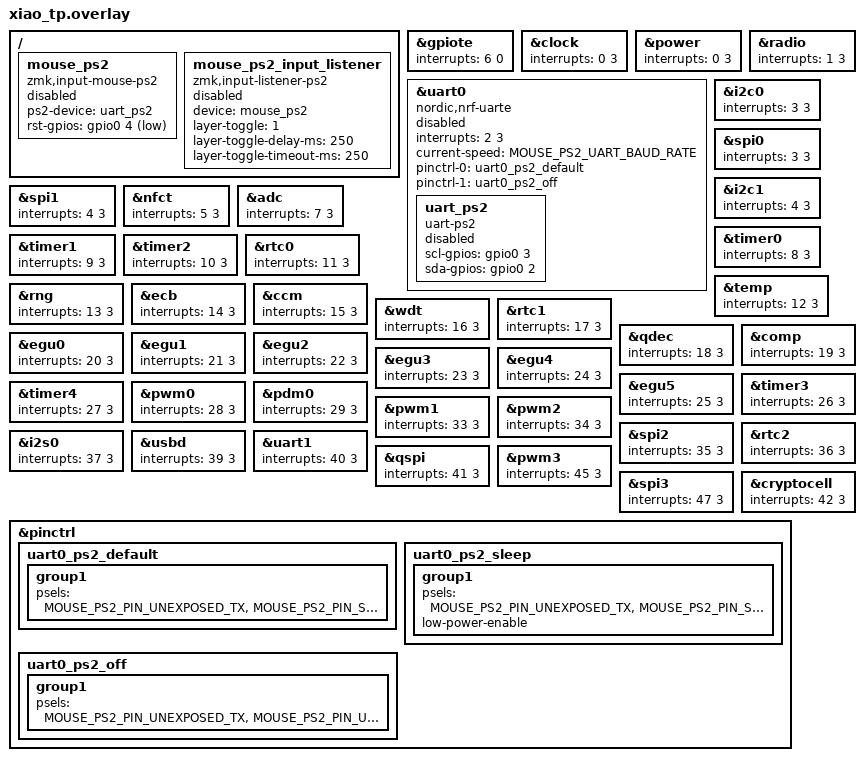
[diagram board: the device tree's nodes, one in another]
/*
 * XIAO TrackPoint Only Shield - PS/2 Configuration
 * Based on corne_tp_right.overlay but adapted for Seeed XIAO BLE
 */

#include "xiao_tp.dtsi"

// Pick the PS/2 driver - Use UART driver for better performance
#define MOUSE_PS2_DRIVER_UART

// Configure pins for Seeed XIAO BLE
// XIAO BLE pin mapping:
// D0 = P0.02, D1 = P0.03, D2 = P0.04, D3 = P0.05, D4 = P0.06, D5 = P0.07
// D6 = P0.08, D7 = P0.09, D8 = P0.10, D9 = P0.11, D10 = P0.12, D11 = P0.13
// PS/2 protocol requires pull-up resistors (4.7kΩ recommended)
// Note: UART handles reading, GPIO handles writing

// Configure SDA pin using pinctrl notation for XIAO BLE
#define MOUSE_PS2_PIN_SDA_PINCTRL <NRF_PSEL(UART_RX, 0, 2)>

// Configure UART BAUD Rate (use default 14400 like Corne example)
#define MOUSE_PS2_UART_BAUD_RATE <14400>

// Unexposed UART pins for XIAO BLE
#define MOUSE_PS2_PIN_UNEXPOSED_TX <NRF_PSEL(UART_TX, 0, 27)>
#define MOUSE_PS2_PIN_UNEXPOSED_RX <NRF_PSEL(UART_RX, 0, 28)>

// Optional: Configure RESET pin if needed (D2 = P0.04)
#define MOUSE_PS2_PIN_RST_PRO_MICRO

// This define can be used in the keymap file to check whether the device tree
// configs in this file are present
#define MOUSE_PS2_DT_PRESENT

// Adjust GPIO interrupt priority to the highest level.
//
// IMPORTANT TLDR:
// PS/2 events must be processed within 30-50us, but frequently bluetooth and
// other interrupts take longer to finish.
//
// Therefore we change the default GPIO priority to the highest level (0) and
// demote all BT interrupt priorities by one level using the kconfig settings:
// - CONFIG_BT_CTLR_LLL_PRIO 1
// - CONFIG_BT_CTLR_ULL_HIGH_PRIO 2
// - CONFIG_BT_CTLR_ULL_LOW_PRIOCONFIG 2
//
// These config options are enabled automatically by the PS2 UART and GPIO
// drivers... so you don't have to enable them manually.
//
// Then we lower the interrupt priority of all other devices by 2 levels using
// the devicetree config below.
//
// This allows the PS/2 interrupts to be triggered faster and reduces
// transmission errors.

// gpiote should have the highest interrupt priority (0)
&gpiote {
    interrupts = < 6 0 >;
};

// All other priorities should be two levels lower than their defaults
// (which is usually 1 and should be demoted to 3)
&clock {
    interrupts = < 0 3 >;
};

&power {
    interrupts = < 0 3 >;
};

&radio {
    interrupts = < 1 3 >;
};

&uart0 {
    interrupts = < 2 3 >;
};

&i2c0 {
    interrupts = < 3 3 >;
};

&spi0 {
    interrupts = < 3 3 >;
};

&i2c1 {
    interrupts = < 4 3 >;
};

&spi1 {
    interrupts = < 4 3 >;
};

&nfct {
    interrupts = < 5 3 >;
};

&adc {
    interrupts = < 7 3 >;
};

&timer0 {
    interrupts = < 8 3 >;
};

&timer1 {
    interrupts = < 9 3 >;
};

&timer2 {
    interrupts = < 10 3 >;
};

&rtc0 {
    interrupts = < 11 3 >;
};

&temp {
    interrupts = < 12 3 >;
};

&rng {
    interrupts = < 13 3 >;
};

&ecb {
    interrupts = < 14 3 >;
};

&ccm {
    interrupts = < 15 3 >;
};

&wdt {
    interrupts = < 16 3 >;
};

&rtc1 {
    interrupts = < 17 3 >;
};

&qdec {
    interrupts = < 18 3 >;
};

&comp {
    interrupts = < 19 3 >;
};

&egu0 {
    interrupts = < 20 3 >;
};

&egu1 {
    interrupts = < 21 3 >;
};

&egu2 {
    interrupts = < 22 3 >;
};

&egu3 {
    interrupts = < 23 3 >;
};

&egu4 {
    interrupts = < 24 3 >;
};

&egu5 {
    interrupts = < 25 3 >;
};

&timer3 {
    interrupts = < 26 3 >;
};

&timer4 {
    interrupts = < 27 3 >;
};

&pwm0 {
    interrupts = < 28 3 >;
};

&pdm0 {
    interrupts = < 29 3 >;
};

&pwm1 {
    interrupts = < 33 3 >;
};

&pwm2 {
    interrupts = < 34 3 >;
};

&spi2 {
    interrupts = < 35 3 >;
};

&rtc2 {
    interrupts = < 36 3 >;
};

&i2s0 {
    interrupts = < 37 3 >;
};

&usbd {
    interrupts = < 39 3 >;
};

&uart1 {
    interrupts = < 40 3 >;
};

&qspi {
    interrupts = < 41 3 >;
};

&pwm3 {
    interrupts = < 45 3 >;
};

&spi3 {
    interrupts = < 47 3 >;
};

&cryptocell {
    interrupts = < 42 3 >;
};

&pinctrl {
	// This pinctrl state is used for receiving
	// For `UART_TX`, set an unused and unexposed pin
	// For `UART_RX`, set the PS/2 SDA pin number
	uart0_ps2_default: uart0_ps2_default {
		group1 {
			psels = MOUSE_PS2_PIN_UNEXPOSED_TX,
					MOUSE_PS2_PIN_SDA_PINCTRL;
		};
	};

	// Set this to the same pins as uart0_ps2_default
	uart0_ps2_sleep: uart0_ps2_sleep {
		group1 {
			psels = MOUSE_PS2_PIN_UNEXPOSED_TX,
					MOUSE_PS2_PIN_SDA_PINCTRL;
			low-power-enable;
		};
	};

	// The nrf52 UART controller is not compatible with the PS/2
	// transmission frame. So the PS/2 UART driver doesn't use UART for
	// transmissions and instead use GPIO bit-banging.
	//
	// When the driver switches to transmit mode, it frees up the SDA pin by
    // switching the UART controller to unexposed/unused pins.
	//
	// Then it configures the GPIO controller to use the SCL and SDA pins
	uart0_ps2_off: uart0_ps2_off {
		group1 {
			psels = MOUSE_PS2_PIN_UNEXPOSED_TX,
					MOUSE_PS2_PIN_UNEXPOSED_RX;
		};
	};
};

#ifdef MOUSE_PS2_DRIVER_UART

    &uart0 {
        status = "disabled";
        compatible = "nordic,nrf-uarte";

        current-speed = MOUSE_PS2_UART_BAUD_RATE;
        pinctrl-0 = <&uart0_ps2_default>;
        pinctrl-1 = <&uart0_ps2_off>;

        pinctrl-names = "default", "sleep";

        uart_ps2: uart_ps2 {
            status="disabled";
            compatible = "uart-ps2";
            scl-gpios = <&gpio0 3 GPIO_ACTIVE_HIGH>;
            sda-gpios = <&gpio0 2 GPIO_ACTIVE_HIGH>;
        };
    };

#else

    / {
        gpio_ps2: gpio_ps2 {
            status = "disabled";

            compatible = "gpio-ps2";
            scl-gpios = <&gpio0 3 GPIO_ACTIVE_HIGH>;
            sda-gpios = <&gpio0 2 GPIO_ACTIVE_HIGH>;
        };
    };

#endif

/ {
    mouse_ps2: mouse_ps2 {
		status = "disabled";
        compatible = "zmk,input-mouse-ps2";

#ifdef MOUSE_PS2_DRIVER_UART
	    ps2-device = <&uart_ps2>;
#else
	    ps2-device = <&gpio_ps2>;
#endif

        rst-gpios = <&gpio0 4 GPIO_ACTIVE_LOW>;

    };

    mouse_ps2_input_listener: mouse_ps2_input_listener {
        compatible = "zmk,input-listener-ps2";
        status = "disabled";

        device = <&mouse_ps2>;

		// Layer toggle settings
		layer-toggle = <1>;
		layer-toggle-delay-ms = <250>;
		layer-toggle-timeout-ms = <250>;
    };
};
